# TN2115s1 register map
Vendor: Fusens Micro Ltd.; Series: TN21xx; File version: 1.0
CPU: CM0 r0p0, little endian, no MPU, no FPU, 2 interrupt priority bits
Registers are 8-bit, read-write, reset 0x0 unless marked. A register's access mark holds for its fields unless they carry their own. Offsets are from the block's base; [hi:lo] are bit positions.

## NFC — NFC System Control
Base 0x40000300
0x00 SYSCTRL — NFC Subsystem Control Register
  [5] PASSTHRUTRG wo — Type 4 mode pass-through trigger
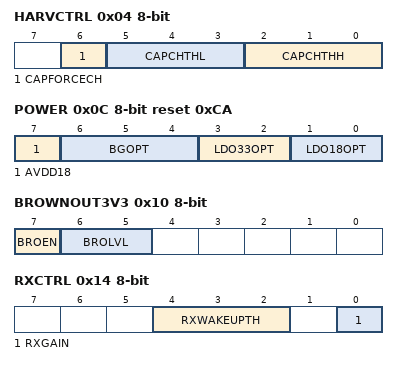
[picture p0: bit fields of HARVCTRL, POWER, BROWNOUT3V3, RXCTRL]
0x04 HARVCTRL — NFC Energy Harvesting Control Register
  [6] CAPFORCECH — Harv2 capacitor force charging
    0=OFF (No force charging); 1=ON (Force charging)
  [5:3] CAPCHTHL — Harv2 capacitor switching voltage Lo threshold selection
    0=2V4 (2.4V); 1=3V0 (3.0V); 2=3V6 (3.6V); 3=4V2 (4.2V); 4=4V8 (4.8V); 5=6V0 (6.0V); 6=7V2 (7.2V); 7=OFF
  [2:0] CAPCHTHH — Harv2 capacitor switching voltage Hi threshold selection
    0=2V7 (2.7V); 1=3V3 (3.3V); 2=3V9 (3.9V); 3=4V5 (4.5V); 4=5V1 (5.1V); 5=6V3 (6.3V); 6=7V5 (7.5V); 7=8V7 (8.7V)
0x08 OPCTRL — NFC Operation Control Register
  [1:0] OPERMODE — NFC Tag interface operation mode
    0=NORF (NFC disabled); 1=NOEEP (NFC no EEPROM access); 2=EEPRO (NFC EEPROM read-only); 3=EEPRW (NFC EEPROM read-write)
0x0C POWER reset 0xCA — System Power and Regulator Control Register
  [7] AVDD18 — AVDD18 rise control
    0=RISE (Rise up AVDD18 upon powerup); 1=NORISE (Do not rise up AVDD18 upon powerup)
  [6:4] BGOPT — Bandgap output voltage control
    0=750mV; 1=714mV; 2=677mV; 3=640mV; 4=604mV; 5=567mV; 6=531mV; 7=494mV
  [3:2] LDO33OPT — 3.3V LDO output voltage control
    0=2V7 (2.7V); 1=3V; 2=3V3 (3.375V); 3=3V8 (3.857V)
  [1:0] LDO18OPT — 1.8V LDO output voltage control
    0=1V5 (1.588V); 1=1V6 (1.6875V); 2=1V8 (1.8V); 3=1V9 (1.928V)
0x10 BROWNOUT3V3 — Brownout Control Register
  [7] BROEN — Brownout Enable
  [6:5] BROLVL — Brownout Voltage Level
    0=2V3 (2.3V); 1=2V5 (2.5V); 2=2V7 (2.7V); 3=2V9 (2.9V)
0x14 RXCTRL — NFC RX Control Register
  [4:2] RXWAKEUPTH — RX wakeup threshold control
    0=25mV; 1=50mV; 2=75mV; 3=100mV; 4=125mV; 5=150mV; 6=175mV; 7=200mV
  [0] RXGAIN — RX GAIN x2
    1=X2 (X2 gain); 0=X1 gain
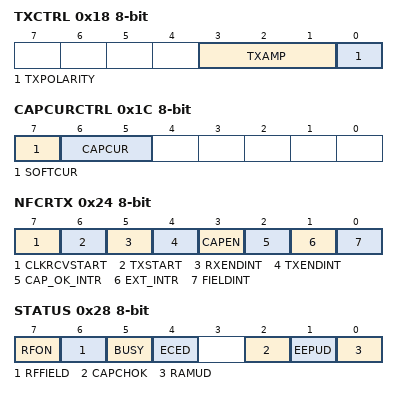
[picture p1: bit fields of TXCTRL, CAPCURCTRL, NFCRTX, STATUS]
0x18 TXCTRL — NFC TX Control Register
  [3:1] TXAMP — TX load modulation strength
  [0] TXPOLARITY — TX modulation polarity
    0=NORMAL (Normal polarity); 1=INV (Inverse polarity)
0x1C CAPCURCTRL — Capacitor Switch Current Control Register
  [7] SOFTCUR — Enable switch soft start
    1=ON (Enable); 0=OFF (Disable)
  [6:5] CAPCUR — Capacitor charge current
    0=Normal current; 1=X05 (Half current); 2=X2 (Double current); 3=Normal current
0x20 OSC — OSC Trimming Register
  [7:0] OSCTRIM — OSC trim value
0x24 NFCRTX
  [7] CLKRCVSTART — NFC start clock recovery
  [6] TXSTART — NFC Start TX
  [5] RXENDINT ro — NFC RX end interrupt
  [4] TXENDINT ro — NFC TX end interrupt
  [3] CAPEN — Enable automatic capacitor charging
  [2] CAP_OK_INTR — Capacitor OK Interrupt Flags
  [1] EXT_INTR — GPIO Interrupt Flags
  [0] FIELDINT — NFC field change interrupt
0x28 STATUS — NFC Status Display Register
  [7] RFON ro — NFC interface on/off
    0=OFF (RF off); 1=ON (RF on)
  [6] RFFIELD ro — NFC field presence
    0=OFF (No RF field); 1=ON (RF field is present)
  [5] BUSY — EEPROM busy
    0=NBUSY (EEPROM not busy); 1=BUSY (EEPROM busy)
  [4] ECED ro — EEPROM ECED status
  [2] CAPCHOK ro — Harv2 capacitor charging status
    0=NFULL (Capacitor not full); 1=FULL (Capacitor full)
  [1] EEPUD — EEPROM update indication
    0=NOUD (No EEP update from NFC); 1=UD (EEP updated from NFC)
  [0] RAMUD — RAM Memory update indication
    0=NOUD (No RAM update from NFC); 1=UD (RAM updated from NFC)
0x2C CLKCALIBVAL — Clock Calibration Result Register
  [7:0] HALFDUR — Calibration Result
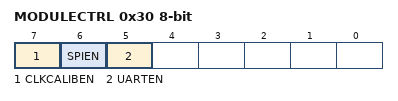
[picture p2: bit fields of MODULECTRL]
0x30 MODULECTRL — Module Enable Register
  [7] CLKCALIBEN — Clock Calibration Enable
  [6] SPIEN — SPI Enable
  [5] UARTEN — UART Enable
0x34 RXGLITCH — RX De-glitch Control Register
  [1:0] GLITCH — Glitch Filter
    0=OFF (Filter off); 1=2CLKS (2 clocks); 2=4CLKS (4 clocks); 3=6CLKS (6 clocks)

## TIM32 — General Purpose 32bit Timer
Base 0x40000404
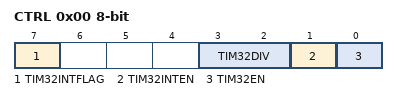
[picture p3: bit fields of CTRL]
0x00 CTRL — TIM32 Control Register
  [7] TIM32INTFLAG — TIM32 interrupt flag
    1=INT_PEND (Interrupt pending); 0=NOINT (No interrupt)
  [3:2] TIM32DIV — TIM32 clock divider
    0=1; 1=2; 16=4; 17=8
  [1] TIM32INTEN — TIM32 interrupt enable control
    1=ON (Enabled); 0=OFF (Disabled)
  [0] TIM32EN — TIM32 enable control
    1=ON (Enabled); 0=OFF (Disabled)
0x04 CNT 32-bit — TIM32 Counter Register
  [31:0] COUNTER — TIM32 counter value
0x08 RELOAD 32-bit — TIM32 Reload Register
  [31:0] RELOAD — TIM32 counter reload value

## UART — UART interface
Base 0x40000200
0x00 DATA — UART RX/TX Data Register
  [7:0] DATA — Data to be txed or data rxed
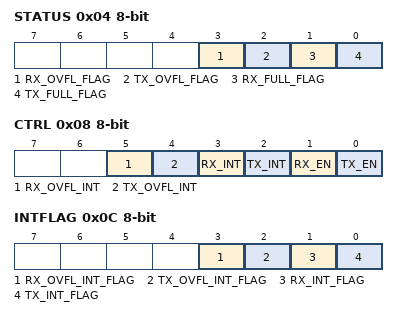
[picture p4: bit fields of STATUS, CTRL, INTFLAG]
0x04 STATUS — UART Status Register
  [3] RX_OVFL_FLAG — RX buffer overflow
  [2] TX_OVFL_FLAG — TX buffer overflow
  [1] RX_FULL_FLAG ro — RX buffer full
  [0] TX_FULL_FLAG ro — TX buffer full
0x08 CTRL — UART Control Register
  [5] RX_OVFL_INT — RX buffer overflow interrupt enable
  [4] TX_OVFL_INT — TX buffer overflow interrupt enable
  [3] RX_INT — RX interrupt enable
  [2] TX_INT — TX interrupt enable
  [1] RX_EN — RX enable
  [0] TX_EN — TX enable
0x0C INTFLAG — UART Interrupt Flag Register
  [3] RX_OVFL_INT_FLAG — RX buffer overflow interrupt flag
  [2] TX_OVFL_INT_FLAG — TX buffer overflow interrupt flag
  [1] RX_INT_FLAG — RX interrupt flag
  [0] TX_INT_FLAG — TX interrupt flag
0x10 BAUDM — UART Baudrate MSB Register
  [7:0] MSB — Baudrate control MSB
0x14 BAUDL — UART Baudrate LSB Register
  [7:0] LSB — Baudrate control LSB
0x18 BAUDF — UART Baudrate Fraction Register
  [7:0] FRC — Baudrate control Fraction

## GPIO
Base 0x40000500
0x00 GPFUNC0 16-bit — GPIO Function Control Register 0
  [12:0] FUNC — Function control
0x04 GPFUNC1 16-bit — GPIO Function Control Register 1
  [12:0] FUNC — Function control
0x08 GPOUT 16-bit — GPIO Output Value Register
  [12:0] OUT — Output Value
0x0C GPIN 16-bit — GPIO Input Value Register
  [12:0] IN ro — Input Value

## FLASH
Base 0x40000600
0x00 FLASHKEY 32-bit — FLASH Lock KEY Register
  [31:0] KEY — The lock key
